AUTOSAR XML (schema 00050)
package /Pkg_ErrorMgrSat_1_0_QM/ComponentTypes
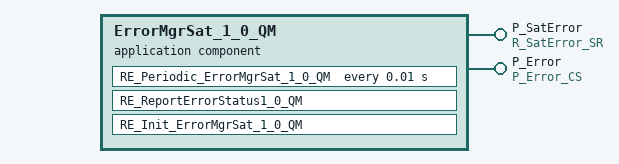
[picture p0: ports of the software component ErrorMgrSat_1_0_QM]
  application sw component type ErrorMgrSat_1_0_QM
    provide port P_SatError: provided-interface=R_SatError_SR
      provided-com-specs:
        data-element=Data_ErrorMgr_ErrorCommPack_1_0_QM, init-value=constant-reference=init_Data_ErrorMgr_ErrorCommPack_1_0_QM
        data-element=Data_ErrorMgr_ErrorCommPack_2_0_QM, init-value=fields=[RunningCounter:0, Checksum:0, Error:[0], Padding:[0, 0, 0], Data:[fields=AdditionalData:[0, 0, 0, 0]]]
        data-element=Data_ErrorMgr_ErrorCommPack_2_1_QM, init-value=fields=[RunningCounter:0, Checksum:0, Error:[0], Padding:[0, 0, 0], Data:[fields=AdditionalData:[0, 0, 0, 0]]]
        data-element=Data_ErrorMgr_ErrorCommPack_QNX_QM, init-value=fields=[RunningCounter:0, Checksum:0, Error:[0], Padding:[0, 0, 0], Data:[fields=AdditionalData:[0, 0, 0, 0]]]
        Data_ErrorMgr_ErrorCommPack_2_0_QM
        Data_ErrorMgr_ErrorCommPack_2_1_QM
        Data_ErrorMgr_ErrorCommPack_QNX_QM
    provide port P_Error: server-com-spec{operation=ReportErrorStatus1_0_QM, queue-length=1}, provided-interface=P_Error_CS
    behavior ErrorMgrSat_1_0_QM_InternalBehavior: handle-termination-and-restart=NO-SUPPORT
      timing event TMT_RE_Periodic_ErrorMgrSat_1_0_QM: start-on-event=RE_Periodic_ErrorMgrSat_1_0_QM, period=0.01
      init event InitEvent: start-on-event=RE_Init_ErrorMgrSat_1_0_QM
      operation invoked event OIT_RE_ReportErrorStatus1_0_QM_P_Error_ReportErrorStatus1_0_QM: start-on-event=RE_ReportErrorStatus1_0_QM, operation=P_Error.ReportErrorStatus1_0_QM
      port-api-options:
        enable-take-address=false, indirect-api=false, port=P_Error
        enable-take-address=false, indirect-api=false, port=P_SatError
      runnable RE_Periodic_ErrorMgrSat_1_0_QM  # Periodic Runnable of Satellite
        data-send-points:
          access SEND_P_SatError_Data_ErrorMgr_ErrorCommPack_1_0_QM: accessed-variable=P_SatError.Data_ErrorMgr_ErrorCommPack_1_0_QM
      runnable RE_ReportErrorStatus1_0_QM: can-be-invoked-concurrently=true  # Server Runnable for handling the error reporting
      runnable RE_Init_ErrorMgrSat_1_0_QM  # Init Runnable
  swc implementation ErrorMgrSat_1_0_QM_Implementation: programming-language=C, vendor-id=0, behavior=ErrorMgrSat_1_0_QM_InternalBehavior
    code-descriptors:
      code Default: artifact-descriptors=autosar-engineering-object=category=SWSRC
